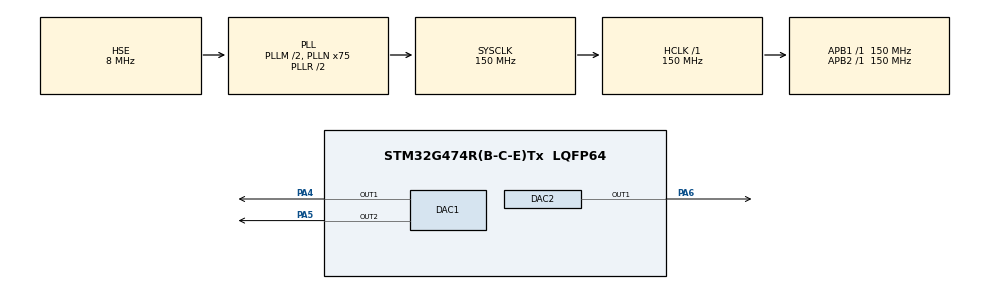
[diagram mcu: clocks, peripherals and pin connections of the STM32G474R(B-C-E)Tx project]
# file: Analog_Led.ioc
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DAC1.DAC_Channel-DAC_OUT2_ExtAndInt=DAC_CHANNEL_2
DAC1.DAC_Trigger_OUT1-DAC_OUT1_ExtAndInt=DAC_TRIGGER_T2_TRGO
DAC1.DAC_Trigger_OUT2-DAC_OUT2_ExtAndInt=DAC_TRIGGER_T2_TRGO
DAC2.DAC_Trigger_OUT1-DAC_OUT1_ExtAndInt=DAC_TRIGGER_T2_TRGO
Dma.DAC1_CH1.1.Direction=DMA_MEMORY_TO_PERIPH
Dma.DAC1_CH1.1.EventEnable=DISABLE
Dma.DAC1_CH1.1.Instance=DMA1_Channel1
Dma.DAC1_CH1.1.MemDataAlignment=DMA_MDATAALIGN_WORD
Dma.DAC1_CH1.1.MemInc=DMA_MINC_ENABLE
Dma.DAC1_CH1.1.Mode=DMA_CIRCULAR
Dma.DAC1_CH1.1.PeriphDataAlignment=DMA_PDATAALIGN_WORD
Dma.DAC1_CH1.1.PeriphInc=DMA_PINC_DISABLE
Dma.DAC1_CH1.1.Polarity=HAL_DMAMUX_REQ_GEN_RISING
Dma.DAC1_CH1.1.Priority=DMA_PRIORITY_LOW
Dma.DAC1_CH1.1.RequestNumber=1
Dma.DAC1_CH1.1.SignalID=NONE
Dma.DAC1_CH1.1.SyncEnable=DISABLE
Dma.DAC1_CH1.1.SyncPolarity=HAL_DMAMUX_SYNC_NO_EVENT
Dma.DAC1_CH1.1.SyncRequestNumber=1
Dma.DAC1_CH1.1.SyncSignalID=NONE
Dma.DAC1_CH2.2.Direction=DMA_MEMORY_TO_PERIPH
Dma.DAC1_CH2.2.EventEnable=DISABLE
Dma.DAC1_CH2.2.Instance=DMA1_Channel2
Dma.DAC1_CH2.2.MemDataAlignment=DMA_MDATAALIGN_WORD
Dma.DAC1_CH2.2.MemInc=DMA_MINC_ENABLE
Dma.DAC1_CH2.2.Mode=DMA_CIRCULAR
Dma.DAC1_CH2.2.PeriphDataAlignment=DMA_PDATAALIGN_WORD
Dma.DAC1_CH2.2.PeriphInc=DMA_PINC_DISABLE
Dma.DAC1_CH2.2.Polarity=HAL_DMAMUX_REQ_GEN_RISING
Dma.DAC1_CH2.2.Priority=DMA_PRIORITY_LOW
Dma.DAC1_CH2.2.RequestNumber=1
Dma.DAC1_CH2.2.SignalID=NONE
Dma.DAC1_CH2.2.SyncEnable=DISABLE
Dma.DAC1_CH2.2.SyncPolarity=HAL_DMAMUX_SYNC_NO_EVENT
Dma.DAC1_CH2.2.SyncRequestNumber=1
Dma.DAC1_CH2.2.SyncSignalID=NONE
Dma.DAC2_CH1.0.Direction=DMA_MEMORY_TO_PERIPH
Dma.DAC2_CH1.0.EventEnable=DISABLE
Dma.DAC2_CH1.0.Instance=DMA1_Channel3
Dma.DAC2_CH1.0.MemDataAlignment=DMA_MDATAALIGN_WORD
Dma.DAC2_CH1.0.MemInc=DMA_MINC_ENABLE
Dma.DAC2_CH1.0.Mode=DMA_CIRCULAR
Dma.DAC2_CH1.0.PeriphDataAlignment=DMA_PDATAALIGN_WORD
Dma.DAC2_CH1.0.PeriphInc=DMA_PINC_DISABLE
Dma.DAC2_CH1.0.Polarity=HAL_DMAMUX_REQ_GEN_RISING
Dma.DAC2_CH1.0.Priority=DMA_PRIORITY_LOW
Dma.DAC2_CH1.0.RequestNumber=1
Dma.DAC2_CH1.0.SignalID=NONE
Dma.DAC2_CH1.0.SyncEnable=DISABLE
Dma.DAC2_CH1.0.SyncPolarity=HAL_DMAMUX_SYNC_NO_EVENT
Dma.DAC2_CH1.0.SyncRequestNumber=1
Dma.DAC2_CH1.0.SyncSignalID=NONE
Dma.Request0=DAC2_CH1
Dma.Request1=DAC1_CH1
Dma.Request2=DAC1_CH2
Mcu.Family=STM32G4
Mcu.Name=STM32G474R(B-C-E)Tx
Mcu.Package=LQFP64
NVIC.DMA1_Channel1_IRQn=true\:0\:0\:false\:false\:true\:false\:true\:true
NVIC.DMA1_Channel2_IRQn=true\:0\:0\:false\:false\:true\:false\:true\:true
NVIC.DMA1_Channel3_IRQn=true\:0\:0\:false\:false\:true\:false\:true\:true
NVIC.PriorityGroup=NVIC_PRIORITYGROUP_4
PA4.Signal=COMP_DAC11_group
PA5.Signal=COMP_DAC12_group
PA6.Signal=COMP_DAC21_group
PF0-OSC_IN.Mode=HSE-External-Oscillator
PF0-OSC_IN.Signal=RCC_OSC_IN
PF1-OSC_OUT.Mode=HSE-External-Oscillator
PF1-OSC_OUT.Signal=RCC_OSC_OUT
ProjectManager.HeapSize=0x200
ProjectManager.StackSize=0x400
ProjectManager.TargetToolchain=STM32CubeIDE
RCC.ADC12Freq_Value=150000000
RCC.ADC345Freq_Value=150000000
RCC.AHBFreq_Value=150000000
RCC.APB1Freq_Value=150000000
RCC.APB1TimFreq_Value=150000000
RCC.APB2Freq_Value=150000000
RCC.APB2TimFreq_Value=150000000
RCC.CortexFreq_Value=150000000
RCC.EXTERNAL_CLOCK_VALUE=12288000
RCC.HCLKFreq_Value=150000000
RCC.HSE_VALUE=8000000
RCC.HSI48_VALUE=48000000
RCC.HSI_VALUE=16000000
RCC.LSE_VALUE=32768
RCC.PLLM=RCC_PLLM_DIV2
RCC.PLLN=75
RCC.PLLSourceVirtual=RCC_PLLSOURCE_HSE
RCC.SYSCLKFreq_VALUE=150000000
RCC.SYSCLKSource=RCC_SYSCLKSOURCE_PLLCLK
RCC.USBFreq_Value=150000000
RCC.VCOOutputFreq_Value=300000000
SH.COMP_DAC11_group.0=DAC1_OUT1,DAC_OUT1_ExtAndInt
SH.COMP_DAC12_group.0=DAC1_OUT2,DAC_OUT2_ExtAndInt
SH.COMP_DAC21_group.0=DAC2_OUT1,DAC_OUT1_ExtAndInt
TIM2.PeriodNoDither=20000-1
TIM2.Prescaler=150-1
TIM2.TIM_MasterOutputTrigger=TIM_TRGO_UPDATE
VP_TIM2_VS_ClockSourceINT.Mode=Internal
board=custom

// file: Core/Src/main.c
/* USER CODE BEGIN Header */
/**
  ******************************************************************************
  * @file           : main.c
  * @brief          : Main program body
  ******************************************************************************
  * @attention
  *
  * Copyright (c) 2023 STMicroelectronics.
  * All rights reserved.
  *
  * This software is licensed under terms that can be found in the LICENSE file
  * in the root directory of this software component.
  * If no LICENSE file comes with this software, it is provided AS-IS.
  *
  ******************************************************************************
  */
/* USER CODE END Header */
#include "main.h"

/* USER CODE BEGIN Includes */
#include "math.h"
/* USER CODE END Includes */

/* USER CODE BEGIN PTD */
#define SAMPLE_SIZE 100
#define PI 3.1415926

uint32_t sine_val[SAMPLE_SIZE];
uint32_t sawtooth_val[SAMPLE_SIZE];
uint32_t traingle_val[SAMPLE_SIZE];

void get_sine_val()
{
	for(int i=0; i<SAMPLE_SIZE; i++)
	{
		sine_val[i] = (sin(i * 2 * PI/SAMPLE_SIZE) + 1) * ((0xfff + 1)/2);
	}
}

void get_sawtooth_val()
{
	for(int i=0; i<SAMPLE_SIZE; i++)
	{
		sawtooth_val[i] = ( fmod(i* 2./SAMPLE_SIZE + 1,  2.) )  * ((0xfff + 1)/2);
	}
}

void get_traingle_val()
{
	float p = SAMPLE_SIZE;
	for(int i=0; i<SAMPLE_SIZE; i++)
	{
		traingle_val[i] =  4./p * fabs( fmod(  fmod(i - p/4., p) + p , p) - p/2. )  * ((0xfff + 1)/2);
	}
}
/* USER CODE END PTD */

DAC_HandleTypeDef hdac1;
DAC_HandleTypeDef hdac2;
DMA_HandleTypeDef hdma_dac1_ch1;
DMA_HandleTypeDef hdma_dac1_ch2;
DMA_HandleTypeDef hdma_dac2_ch1;

TIM_HandleTypeDef htim2;

void SystemClock_Config(void);
static void MX_GPIO_Init(void);
static void MX_DMA_Init(void);
static void MX_DAC1_Init(void);
static void MX_DAC2_Init(void);
static void MX_TIM2_Init(void);

int main(void)
{

  /* MCU Configuration--------------------------------------------------------*/

  /* Reset of all peripherals, Initializes the Flash interface and the Systick. */
  HAL_Init();

  /* Configure the system clock */
  SystemClock_Config();

  /* Initialize all configured peripherals */
  MX_GPIO_Init();
  MX_DMA_Init();
  MX_DAC1_Init();
  MX_DAC2_Init();
  MX_TIM2_Init();
  /* USER CODE BEGIN 2 */

  HAL_TIM_Base_Start(&htim2);

  //dioda R podłączona do pinu PA4
  get_sine_val();
  HAL_DAC_Start_DMA(&hdac1, DAC_CHANNEL_1, sine_val, SAMPLE_SIZE, DAC_ALIGN_12B_R);

  //dioda G podłączona do pinu PA5
  get_sawtooth_val();
  HAL_DAC_Start_DMA(&hdac1, DAC_CHANNEL_2, sawtooth_val, SAMPLE_SIZE, DAC_ALIGN_12B_R);

  //dioda B podłączona do pinu PA6
  get_traingle_val();
  HAL_DAC_Start_DMA(&hdac2, DAC_CHANNEL_1, traingle_val, SAMPLE_SIZE, DAC_ALIGN_12B_R);
  /* USER CODE BEGIN 2 */

  /* USER CODE END 2 */

  /* Infinite loop */
  while (1)
  {

  }
}

void SystemClock_Config(void)
{
  RCC_OscInitTypeDef RCC_OscInitStruct = {0};
  RCC_ClkInitTypeDef RCC_ClkInitStruct = {0};

  /** Configure the main internal regulator output voltage
  */
  HAL_PWREx_ControlVoltageScaling(PWR_REGULATOR_VOLTAGE_SCALE1);

  /** Initializes the RCC Oscillators according to the specified parameters
  * in the RCC_OscInitTypeDef structure.
  */
  RCC_OscInitStruct.OscillatorType = RCC_OSCILLATORTYPE_HSE;
  RCC_OscInitStruct.HSEState = RCC_HSE_ON;
  RCC_OscInitStruct.PLL.PLLState = RCC_PLL_ON;
  RCC_OscInitStruct.PLL.PLLSource = RCC_PLLSOURCE_HSE;
  RCC_OscInitStruct.PLL.PLLM = RCC_PLLM_DIV2;
  RCC_OscInitStruct.PLL.PLLN = 75;
  RCC_OscInitStruct.PLL.PLLP = RCC_PLLP_DIV2;
  RCC_OscInitStruct.PLL.PLLQ = RCC_PLLQ_DIV2;
  RCC_OscInitStruct.PLL.PLLR = RCC_PLLR_DIV2;
  if (HAL_RCC_OscConfig(&RCC_OscInitStruct) != HAL_OK)
  {
    Error_Handler();
  }

  /** Initializes the CPU, AHB and APB buses clocks
  */
  RCC_ClkInitStruct.ClockType = RCC_CLOCKTYPE_HCLK|RCC_CLOCKTYPE_SYSCLK
                              |RCC_CLOCKTYPE_PCLK1|RCC_CLOCKTYPE_PCLK2;
  RCC_ClkInitStruct.SYSCLKSource = RCC_SYSCLKSOURCE_PLLCLK;
  RCC_ClkInitStruct.AHBCLKDivider = RCC_SYSCLK_DIV1;
  RCC_ClkInitStruct.APB1CLKDivider = RCC_HCLK_DIV1;
  RCC_ClkInitStruct.APB2CLKDivider = RCC_HCLK_DIV1;

  if (HAL_RCC_ClockConfig(&RCC_ClkInitStruct, FLASH_LATENCY_4) != HAL_OK)
  {
    Error_Handler();
  }
}

static void MX_DAC1_Init(void)
{

  DAC_ChannelConfTypeDef sConfig = {0};

  /** DAC Initialization
  */
  hdac1.Instance = DAC1;
  if (HAL_DAC_Init(&hdac1) != HAL_OK)
  {
    Error_Handler();
  }

  /** DAC channel OUT1 config
  */
  sConfig.DAC_HighFrequency = DAC_HIGH_FREQUENCY_INTERFACE_MODE_AUTOMATIC;
  sConfig.DAC_DMADoubleDataMode = DISABLE;
  sConfig.DAC_SignedFormat = DISABLE;
  sConfig.DAC_SampleAndHold = DAC_SAMPLEANDHOLD_DISABLE;
  sConfig.DAC_Trigger = DAC_TRIGGER_T2_TRGO;
  sConfig.DAC_Trigger2 = DAC_TRIGGER_NONE;
  sConfig.DAC_OutputBuffer = DAC_OUTPUTBUFFER_ENABLE;
  sConfig.DAC_ConnectOnChipPeripheral = DAC_CHIPCONNECT_BOTH;
  sConfig.DAC_UserTrimming = DAC_TRIMMING_FACTORY;
  if (HAL_DAC_ConfigChannel(&hdac1, &sConfig, DAC_CHANNEL_1) != HAL_OK)
  {
    Error_Handler();
  }

  /** DAC channel OUT2 config
  */
  if (HAL_DAC_ConfigChannel(&hdac1, &sConfig, DAC_CHANNEL_2) != HAL_OK)
  {
    Error_Handler();
  }

}

static void MX_DAC2_Init(void)
{

  DAC_ChannelConfTypeDef sConfig = {0};

  /** DAC Initialization
  */
  hdac2.Instance = DAC2;
  if (HAL_DAC_Init(&hdac2) != HAL_OK)
  {
    Error_Handler();
  }

  /** DAC channel OUT1 config
  */
  sConfig.DAC_HighFrequency = DAC_HIGH_FREQUENCY_INTERFACE_MODE_AUTOMATIC;
  sConfig.DAC_DMADoubleDataMode = DISABLE;
  sConfig.DAC_SignedFormat = DISABLE;
  sConfig.DAC_SampleAndHold = DAC_SAMPLEANDHOLD_DISABLE;
  sConfig.DAC_Trigger = DAC_TRIGGER_T2_TRGO;
  sConfig.DAC_Trigger2 = DAC_TRIGGER_NONE;
  sConfig.DAC_OutputBuffer = DAC_OUTPUTBUFFER_ENABLE;
  sConfig.DAC_ConnectOnChipPeripheral = DAC_CHIPCONNECT_BOTH;
  sConfig.DAC_UserTrimming = DAC_TRIMMING_FACTORY;
  if (HAL_DAC_ConfigChannel(&hdac2, &sConfig, DAC_CHANNEL_1) != HAL_OK)
  {
    Error_Handler();
  }

}

static void MX_TIM2_Init(void)
{

  TIM_ClockConfigTypeDef sClockSourceConfig = {0};
  TIM_MasterConfigTypeDef sMasterConfig = {0};

  htim2.Instance = TIM2;
  htim2.Init.Prescaler = 150-1;
  htim2.Init.CounterMode = TIM_COUNTERMODE_UP;
  htim2.Init.Period = 19999;
  htim2.Init.ClockDivision = TIM_CLOCKDIVISION_DIV1;
  htim2.Init.AutoReloadPreload = TIM_AUTORELOAD_PRELOAD_DISABLE;
  if (HAL_TIM_Base_Init(&htim2) != HAL_OK)
  {
    Error_Handler();
  }
  sClockSourceConfig.ClockSource = TIM_CLOCKSOURCE_INTERNAL;
  if (HAL_TIM_ConfigClockSource(&htim2, &sClockSourceConfig) != HAL_OK)
  {
    Error_Handler();
  }
  sMasterConfig.MasterOutputTrigger = TIM_TRGO_UPDATE;
  sMasterConfig.MasterSlaveMode = TIM_MASTERSLAVEMODE_DISABLE;
  if (HAL_TIMEx_MasterConfigSynchronization(&htim2, &sMasterConfig) != HAL_OK)
  {
    Error_Handler();
  }

}

static void MX_DMA_Init(void)
{

  /* DMA controller clock enable */
  __HAL_RCC_DMAMUX1_CLK_ENABLE();
  __HAL_RCC_DMA1_CLK_ENABLE();

  /* DMA interrupt init */
  /* DMA1_Channel1_IRQn interrupt configuration */
  HAL_NVIC_SetPriority(DMA1_Channel1_IRQn, 0, 0);
  HAL_NVIC_EnableIRQ(DMA1_Channel1_IRQn);
  /* DMA1_Channel2_IRQn interrupt configuration */
  HAL_NVIC_SetPriority(DMA1_Channel2_IRQn, 0, 0);
  HAL_NVIC_EnableIRQ(DMA1_Channel2_IRQn);
  /* DMA1_Channel3_IRQn interrupt configuration */
  HAL_NVIC_SetPriority(DMA1_Channel3_IRQn, 0, 0);
  HAL_NVIC_EnableIRQ(DMA1_Channel3_IRQn);

}

static void MX_GPIO_Init(void)
{

  /* GPIO Ports Clock Enable */
  __HAL_RCC_GPIOF_CLK_ENABLE();
  __HAL_RCC_GPIOA_CLK_ENABLE();

}

void Error_Handler(void)
{
  __disable_irq();
  while (1)
  {
  }
}
